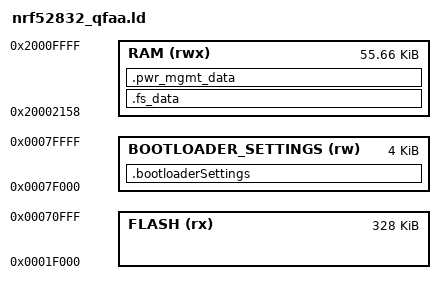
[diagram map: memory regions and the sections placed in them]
/* Linker script to configure memory regions. */

SEARCH_DIR(.)
GROUP(-lgcc -lc -lnosys)

MEMORY
{
  FLASH (rx) : ORIGIN = 0x1f000, LENGTH = 0x75000 - 0x1f000 - (4 * 0x1000)
  RAM (rwx) :  ORIGIN = 0x20002158, LENGTH = 0xdea8
  BOOTLOADER_SETTINGS (rw) : ORIGIN = 0x0007F000, LENGTH = 0x1000
}

SECTIONS
{
  /* Ensures the bootloader settings are placed at the last flash page. */
  .bootloaderSettings(NOLOAD) :
  {

  } > BOOTLOADER_SETTINGS
  .fs_data :
  {
    PROVIDE(__start_fs_data = .);
    KEEP(*(.fs_data))
    PROVIDE(__stop_fs_data = .);
  } > RAM
  .pwr_mgmt_data :
  {
    PROVIDE(__start_pwr_mgmt_data = .);
    KEEP(*(.pwr_mgmt_data))
    PROVIDE(__stop_pwr_mgmt_data = .);
  } > RAM
} INSERT AFTER .data;

INCLUDE "nrf5x_common.ld"
